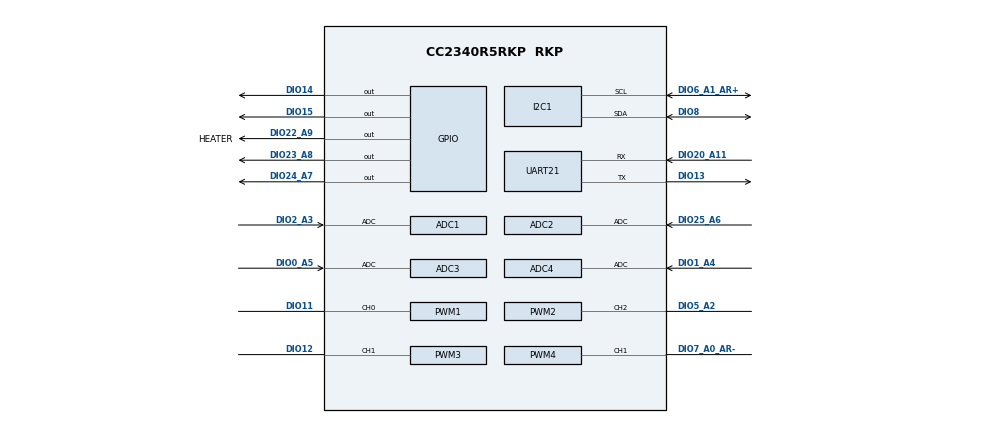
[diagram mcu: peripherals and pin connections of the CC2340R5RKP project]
/**
 * @cliArgs --device "CC2340R5RKP" --part "Default" --package "RKP" --rtos "freertos" --product "simplelink_lowpower_f3_sdk@9.12.00.19"
 * @versions {"tool":"1.23.2+4156"}
 */

/**
 * Import the modules used in this configuration.
 */
const FreeRTOS    = scripting.addModule("/freertos/FreeRTOS");
const ble         = scripting.addModule("/ti/ble/ble");
const CCFG        = scripting.addModule("/ti/devices/CCFG");
const rfdesign    = scripting.addModule("/ti/devices/radioconfig/rfdesign");
const ADC         = scripting.addModule("/ti/drivers/ADC", {}, false);
const ADC1        = ADC.addInstance();
const ADC2        = ADC.addInstance();
const ADC3        = ADC.addInstance();
const ADC4        = ADC.addInstance();
const AESCCM      = scripting.addModule("/ti/drivers/AESCCM");
const AESCCM1     = AESCCM.addInstance();
const AESCTRDRBG  = scripting.addModule("/ti/drivers/AESCTRDRBG");
const AESCTRDRBG1 = AESCTRDRBG.addInstance();
const AESECB      = scripting.addModule("/ti/drivers/AESECB");
const AESECB1     = AESECB.addInstance();
const ECDH        = scripting.addModule("/ti/drivers/ECDH");
const ECDH1       = ECDH.addInstance();
const GPIO        = scripting.addModule("/ti/drivers/GPIO");
const GPIO5       = GPIO.addInstance();
const GPIO6       = GPIO.addInstance();
const GPIO7       = GPIO.addInstance();
const GPIO8       = GPIO.addInstance();
const GPIO19      = GPIO.addInstance();
const I2C         = scripting.addModule("/ti/drivers/I2C", {}, false);
const I2C1        = I2C.addInstance();
const NVS         = scripting.addModule("/ti/drivers/NVS");
const NVS1        = NVS.addInstance();
const NVS2        = NVS.addInstance();
const PWM         = scripting.addModule("/ti/drivers/PWM", {}, false);
const PWM1        = PWM.addInstance();
const PWM2        = PWM.addInstance();
const PWM3        = PWM.addInstance();
const PWM4        = PWM.addInstance();
const Power       = scripting.addModule("/ti/drivers/Power");
const RCL         = scripting.addModule("/ti/drivers/RCL");
const RNG         = scripting.addModule("/ti/drivers/RNG");
const RNG1        = RNG.addInstance();
const UART2       = scripting.addModule("/ti/drivers/UART2", {}, false);
const UART21      = UART2.addInstance();
const Button      = scripting.addModule("/ti/drivers/apps/Button", {}, false);
const Button1     = Button.addInstance();
const Button2     = Button.addInstance();
const Settings    = scripting.addModule("/ti/posix/freertos/Settings");

/**
 * Write custom configuration values to the imported modules.
 */
FreeRTOS.heapSize       = 0x00004D50;
FreeRTOS.timerStackSize = 0x00000190;
FreeRTOS.idleStackSize  = 0x00000130;

ble.basicBLE                                                   = true;
ble.disDevBySerUuid                                            = true;
ble.deviceName                                                 = "Basic BLE project";
ble.numOfAdvSets                                               = 1;
ble.numOfDefAdvSets                                            = 1;
ble.disableDisplayModule                                       = true;
ble.radioConfig.codeExportConfig.$name                         = "ti_devices_radioconfig_code_export_param0";
ble.adcNoiseConfig.codeExportConfig.$name                      = "ti_devices_radioconfig_code_export_param1";
ble.bleCsConfig.codeExportConfig.$name                         = "ti_devices_radioconfig_code_export_param2";
ble.connUpdateParamsPeripheral.$name                           = "ti_ble_general_ble_conn_update_params0";
ble.advSet1.$name                                              = "ti_ble_broadcaster_advertisement_set0";
ble.advSet1.advParam1.$name                                    = "ti_ble_broadcaster_advertisement_params0";
ble.advSet1.advData1.$name                                     = "ti_ble_broadcaster_advertisement_data0";
ble.advSet1.advData1.GAP_ADTYPE_16BIT_MORE                     = true;
ble.advSet1.advData1.numOfUUIDs16More                          = 1;
ble.advSet1.advData1.UUID016More                               = 0xFFF0;
ble.advSet1.scanRes1.$name                                     = "ti_ble_broadcaster_advertisement_data1";
ble.advSet1.scanRes1.GAP_ADTYPE_PERIPHERAL_CONN_INTERVAL_RANGE = true;

CCFG.bldrSetting        = "Default FCFG bootloader, with CCFG settings";
CCFG.ccfgTemplate.$name = "ti_devices_CCFG_CCFGCC23X0Template0";

ADC1.$name                         = "CONFIG_ADC_0";
ADC1.adcChannel.adc.adcPin.$assign = "DIO2_A3";

ADC2.$name                         = "CONFIG_ADC_1";
ADC2.adcChannel.adc.adcPin.$assign = "DIO25_A6";

ADC3.$name                         = "CONFIG_ADC_2";
ADC3.adcChannel.adc.adcPin.$assign = "DIO0_A5";

ADC4.$name                         = "CONFIG_ADC_3";
ADC4.adcChannel.adc.adcPin.$assign = "DIO1_A4";

AESCCM1.$name = "CONFIG_AESCCM0";

AESCTRDRBG1.$name = "CONFIG_AESCTRDRBG_0";

AESECB1.$name = "CONFIG_AESECB0";

ECDH1.$name = "CONFIG_ECDH0";

GPIO5.mode            = "Output";
GPIO5.$name           = "CONFIG_GPIO_LED_GREEN";
GPIO5.gpioPin.$assign = "DIO15";

GPIO6.mode            = "Output";
GPIO6.$name           = "CONFIG_GPIO_LED_RED";
GPIO6.gpioPin.$assign = "DIO14";

GPIO7.$name           = "CONFIG_GPIO_0";
GPIO7.gpioPin.$assign = "DIO23_A8";

GPIO8.$name           = "CONFIG_GPIO_1";
GPIO8.gpioPin.$assign = "DIO24_A7";

GPIO19.$name           = "HEATER";
GPIO19.mode            = "Output";
GPIO19.gpioPin.$assign = "DIO22_A9";

I2C1.$name              = "CONFIG_I2C_0";
I2C1.i2c.$assign        = "I2C0";
I2C1.i2c.sdaPin.$assign = "DIO8";
I2C1.i2c.sclPin.$assign = "DIO6_A1_AR+";

NVS1.$name                    = "CONFIG_NVSINTERNAL";
NVS1.internalFlash.$name      = "ti_drivers_nvs_NVSLPF30";
NVS1.internalFlash.regionBase = 0x7D000;
NVS1.internalFlash.regionSize = 0x3000;

NVS2.$name                    = "CONFIG_NVS_0";
NVS2.internalFlash.$name      = "ti_drivers_nvs_NVSLPF31";
NVS2.internalFlash.regionBase = 0x10000;
NVS2.internalFlash.regionSize = 0x4000;

PWM1.$name                            = "CONFIG_PWM_0";
PWM1.prescalerDivider                 = 255;
PWM1.timerObject.$name                = "CONFIG_LGPTIMER_0";
PWM1.timerObject.channel0Connection   = "Pin";
PWM1.timerObject.timer.$assign        = "LGPT0";
PWM1.timerObject.timer.ch0Pin.$assign = "DIO11";

PWM2.$name                            = "CONFIG_PWM_1";
PWM2.prescalerDivider                 = 255;
PWM2.timerObject.$name                = "CONFIG_LGPTIMER_1";
PWM2.timerObject.channel2Connection   = "Pin";
PWM2.timerObject.timer.$assign        = "LGPT2";
PWM2.timerObject.timer.ch2Pin.$assign = "DIO5_A2";

PWM3.$name                            = "CONFIG_PWM_2";
PWM3.prescalerDivider                 = 255;
PWM3.timerObject.$name                = "CONFIG_LGPTIMER_2";
PWM3.timerObject.channel1Connection   = "Pin";
PWM3.timerObject.timer.$assign        = "LGPT1";
PWM3.timerObject.timer.ch1Pin.$assign = "DIO12";

PWM4.$name                            = "CONFIG_PWM_3";
PWM4.prescalerDivider                 = 255;
PWM4.timerObject.$name                = "CONFIG_LGPTIMER_3";
PWM4.timerObject.channel1Connection   = "Pin";
PWM4.timerObject.timer.$assign        = "LGPT3";
PWM4.timerObject.timer.ch1Pin.$assign = "DIO7_A0_AR-";

RNG.rngReturnBehavior = "RNG_RETURN_BEHAVIOR_BLOCKING";

RNG1.$name = "CONFIG_RNG_0";

UART21.$name              = "CONFIG_UART2_0";
UART21.uart.$assign       = "UART0";
UART21.uart.txPin.$assign = "DIO13";
UART21.uart.rxPin.$assign = "DIO20_A11";

Button1.$name          = "CONFIG_BUTTON_0";
Button1.button.$assign = "DIO10";

Button2.$name          = "CONFIG_BUTTON_1";
Button2.button.$assign = "DIO9";

/**
 * Pinmux solution for unlocked pins/peripherals. This ensures that minor changes to the automatic solver in a future
 * version of the tool will not impact the pinmux you originally saw.  These lines can be completely deleted in order to
 * re-solve from scratch.
 */
ADC1.adcChannel.adc.$suggestSolution      = "ADC";
ADC2.adcChannel.adc.$suggestSolution      = "ADC";
ADC3.adcChannel.adc.$suggestSolution      = "ADC";
ADC4.adcChannel.adc.$suggestSolution      = "ADC";
UART21.uart.dmaTxChannel.$suggestSolution = "DMA_CH1";
UART21.uart.dmaRxChannel.$suggestSolution = "DMA_CH0";
